AUTOSAR XML (schema 4-0-3)
standard types defined: Boolean, UInt16, UInt8
package /AUTOSAR_Platform/DataConstrs
  range DC_Boolean: raw 0..1
  range DC_UInt16: raw 0..65535
  range DC_UInt8: raw 0..255
package /PATAC/MSM/ComponentTypes
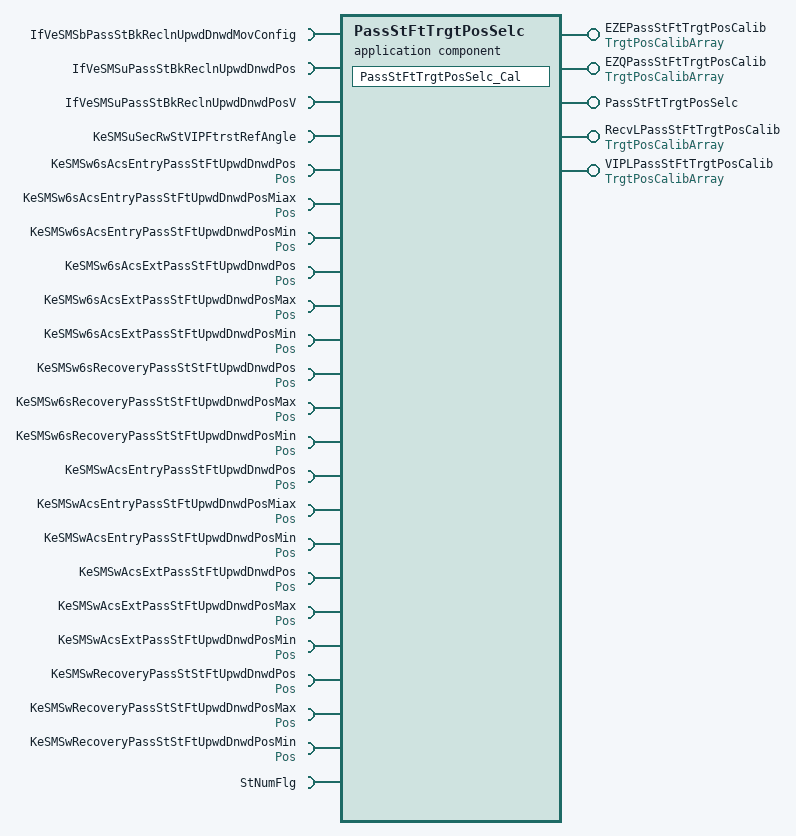
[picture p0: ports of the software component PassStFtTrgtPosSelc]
  application sw component type PassStFtTrgtPosSelc
    5 x provide port:
      EZEPassStFtTrgtPosCalib: nonqueued-sender-com-spec{data-element=TrgtPosArray, init-value=[4095, 4095, 4095]}, provided-interface=TrgtPosCalibArray
      EZQPassStFtTrgtPosCalib: nonqueued-sender-com-spec{data-element=TrgtPosArray, init-value=[4095, 4095, 4095]}, provided-interface=TrgtPosCalibArray
      PassStFtTrgtPosSelc: server-com-spec{operation=Cal, queue-length=1}, provided-interface=PassStFtTrgtPosSelc
      RecvLPassStFtTrgtPosCalib: nonqueued-sender-com-spec{data-element=TrgtPosArray, init-value=[4095, 4095, 4095]}, provided-interface=TrgtPosCalibArray
      VIPLPassStFtTrgtPosCalib: nonqueued-sender-com-spec{data-element=TrgtPosArray, init-value=[4095, 4095, 4095]}, provided-interface=TrgtPosCalibArray
    23 x require port:
      IfVeSMSbPassStBkReclnUpwdDnwdMovConfig: nonqueued-receiver-com-spec{data-element=IfVeSMSbPassStBkReclnUpwdDnwdMovConfig/Val, filter=data-filter-type=ALWAYS, init-value=0}, required-interface=IfVeSMSbPassStBkReclnUpwdDnwdMovConfig
      IfVeSMSuPassStBkReclnUpwdDnwdPos: nonqueued-receiver-com-spec{data-element=IfVeSMSuPassStBkReclnUpwdDnwdPos/Val, filter=data-filter-type=ALWAYS, init-value=0}, required-interface=IfVeSMSuPassStBkReclnUpwdDnwdPos
      IfVeSMSuPassStBkReclnUpwdDnwdPosV: nonqueued-receiver-com-spec{data-element=IfVeSMSuPassStBkReclnUpwdDnwdPosV/Val, filter=data-filter-type=ALWAYS, init-value=0}, required-interface=IfVeSMSuPassStBkReclnUpwdDnwdPosV
      KeSMSuSecRwStVIPFtrstRefAngle: parameter-require-com-spec{init-value=110, parameter=KeSMSuSecRwStVIPFtrstRefAngle/Val}, required-interface=KeSMSuSecRwStVIPFtrstRefAngle
      KeSMSw6sAcsEntryPassStFtUpwdDnwdPos: parameter-require-com-spec{init-value=0, parameter=Pos/Val}, required-interface=Pos
      KeSMSw6sAcsEntryPassStFtUpwdDnwdPosMiax: parameter-require-com-spec{init-value=0, parameter=Pos/Val}, required-interface=Pos
      KeSMSw6sAcsEntryPassStFtUpwdDnwdPosMin: parameter-require-com-spec{init-value=0, parameter=Pos/Val}, required-interface=Pos
      KeSMSw6sAcsExtPassStFtUpwdDnwdPos: parameter-require-com-spec{init-value=0, parameter=Pos/Val}, required-interface=Pos
      KeSMSw6sAcsExtPassStFtUpwdDnwdPosMax: parameter-require-com-spec{init-value=0, parameter=Pos/Val}, required-interface=Pos
      KeSMSw6sAcsExtPassStFtUpwdDnwdPosMin: parameter-require-com-spec{init-value=0, parameter=Pos/Val}, required-interface=Pos
      KeSMSw6sRecoveryPassStStFtUpwdDnwdPos: parameter-require-com-spec{init-value=0, parameter=Pos/Val}, required-interface=Pos
      KeSMSw6sRecoveryPassStStFtUpwdDnwdPosMax: parameter-require-com-spec{init-value=0, parameter=Pos/Val}, required-interface=Pos
      KeSMSw6sRecoveryPassStStFtUpwdDnwdPosMin: parameter-require-com-spec{init-value=0, parameter=Pos/Val}, required-interface=Pos
      KeSMSwAcsEntryPassStFtUpwdDnwdPos: parameter-require-com-spec{init-value=0, parameter=Pos/Val}, required-interface=Pos
      KeSMSwAcsEntryPassStFtUpwdDnwdPosMiax: parameter-require-com-spec{init-value=0, parameter=Pos/Val}, required-interface=Pos
      KeSMSwAcsEntryPassStFtUpwdDnwdPosMin: parameter-require-com-spec{init-value=0, parameter=Pos/Val}, required-interface=Pos
      KeSMSwAcsExtPassStFtUpwdDnwdPos: parameter-require-com-spec{init-value=0, parameter=Pos/Val}, required-interface=Pos
      KeSMSwAcsExtPassStFtUpwdDnwdPosMax: parameter-require-com-spec{init-value=0, parameter=Pos/Val}, required-interface=Pos
      KeSMSwAcsExtPassStFtUpwdDnwdPosMin: parameter-require-com-spec{init-value=0, parameter=Pos/Val}, required-interface=Pos
      KeSMSwRecoveryPassStStFtUpwdDnwdPos: parameter-require-com-spec{init-value=0, parameter=Pos/Val}, required-interface=Pos
      KeSMSwRecoveryPassStStFtUpwdDnwdPosMax: parameter-require-com-spec{init-value=0, parameter=Pos/Val}, required-interface=Pos
      KeSMSwRecoveryPassStStFtUpwdDnwdPosMin: parameter-require-com-spec{init-value=0, parameter=Pos/Val}, required-interface=Pos
      StNumFlg: required-interface=StNumFlg
        required-com-specs:
          data-element=Is4s, filter=data-filter-type=ALWAYS, init-value=0
          data-element=Is6s, filter=data-filter-type=ALWAYS, init-value=0
          data-element=Is6s7s, filter=data-filter-type=ALWAYS, init-value=0
          data-element=Is7s, filter=data-filter-type=ALWAYS, init-value=0
    behavior PassStFtTrgtPosSelc_InternalBehavior
      operation invoked event OIT_PassStFtTrgtPosSelc_Cal_PassStFtTrgtPosSelc_Cal: start-on-event=PassStFtTrgtPosSelc_Cal, operation=PassStFtTrgtPosSelc.Cal
      runnable PassStFtTrgtPosSelc_Cal
        data-receive-point-by-arguments:
          7 x access:
            REC_IfVeSMSbPassStBkReclnUpwdDnwdMovConfig_Val: accessed-variable=IfVeSMSbPassStBkReclnUpwdDnwdMovConfig.Val
            REC_IfVeSMSuPassStBkReclnUpwdDnwdPos_Val: accessed-variable=IfVeSMSuPassStBkReclnUpwdDnwdPos.Val
            REC_IfVeSMSuPassStBkReclnUpwdDnwdPosV_Val: accessed-variable=IfVeSMSuPassStBkReclnUpwdDnwdPosV.Val
            REC_StNumFlg_Is4s: accessed-variable=StNumFlg.Is4s
            REC_StNumFlg_Is6s: accessed-variable=StNumFlg.Is6s
            REC_StNumFlg_Is6s7s: accessed-variable=StNumFlg.Is6s7s
            REC_StNumFlg_Is7s: accessed-variable=StNumFlg.Is7s
        data-send-points:
          4 x access:
            SEND_EZEPassStFtTrgtPosCalib_TrgtPosArray: accessed-variable=EZEPassStFtTrgtPosCalib.TrgtPosArray
            SEND_EZQPassStFtTrgtPosCalib_TrgtPosArray: accessed-variable=EZQPassStFtTrgtPosCalib.TrgtPosArray
            SEND_RecvLPassStFtTrgtPosCalib_TrgtPosArray: accessed-variable=RecvLPassStFtTrgtPosCalib.TrgtPosArray
            SEND_VIPLPassStFtTrgtPosCalib_TrgtPosArray: accessed-variable=VIPLPassStFtTrgtPosCalib.TrgtPosArray
        19 x parameter access:
          PA_KeSMSuSecRwStVIPFtrstRefAngle_Val: accessed-parameter=KeSMSuSecRwStVIPFtrstRefAngle.Val
          PA_KeSMSw6sAcsEntryPassStFtUpwdDnwdPos_Val: accessed-parameter=KeSMSw6sAcsEntryPassStFtUpwdDnwdPos.Val
          PA_KeSMSw6sAcsEntryPassStFtUpwdDnwdPosMiax_Val: accessed-parameter=KeSMSw6sAcsEntryPassStFtUpwdDnwdPosMiax.Val
          PA_KeSMSw6sAcsEntryPassStFtUpwdDnwdPosMin_Val: accessed-parameter=KeSMSw6sAcsEntryPassStFtUpwdDnwdPosMin.Val
          PA_KeSMSw6sAcsExtPassStFtUpwdDnwdPos_Val: accessed-parameter=KeSMSw6sAcsExtPassStFtUpwdDnwdPos.Val
          PA_KeSMSw6sAcsExtPassStFtUpwdDnwdPosMax_Val: accessed-parameter=KeSMSw6sAcsExtPassStFtUpwdDnwdPosMax.Val
          PA_KeSMSw6sAcsExtPassStFtUpwdDnwdPosMin_Val: accessed-parameter=KeSMSw6sAcsExtPassStFtUpwdDnwdPosMin.Val
          PA_KeSMSw6sRecoveryPassStStFtUpwdDnwdPos_Val: accessed-parameter=KeSMSw6sRecoveryPassStStFtUpwdDnwdPos.Val
          PA_KeSMSw6sRecoveryPassStStFtUpwdDnwdPosMax_Val: accessed-parameter=KeSMSw6sRecoveryPassStStFtUpwdDnwdPosMax.Val
          PA_KeSMSw6sRecoveryPassStStFtUpwdDnwdPosMin_Val: accessed-parameter=KeSMSw6sRecoveryPassStStFtUpwdDnwdPosMin.Val
          PA_KeSMSwAcsEntryPassStFtUpwdDnwdPos_Val: accessed-parameter=KeSMSwAcsEntryPassStFtUpwdDnwdPos.Val
          PA_KeSMSwAcsEntryPassStFtUpwdDnwdPosMiax_Val: accessed-parameter=KeSMSwAcsEntryPassStFtUpwdDnwdPosMiax.Val
          PA_KeSMSwAcsEntryPassStFtUpwdDnwdPosMin_Val: accessed-parameter=KeSMSwAcsEntryPassStFtUpwdDnwdPosMin.Val
          PA_KeSMSwAcsExtPassStFtUpwdDnwdPos_Val: accessed-parameter=KeSMSwAcsExtPassStFtUpwdDnwdPos.Val
          PA_KeSMSwAcsExtPassStFtUpwdDnwdPosMax_Val: accessed-parameter=KeSMSwAcsExtPassStFtUpwdDnwdPosMax.Val
          PA_KeSMSwAcsExtPassStFtUpwdDnwdPosMin_Val: accessed-parameter=KeSMSwAcsExtPassStFtUpwdDnwdPosMin.Val
          PA_KeSMSwRecoveryPassStStFtUpwdDnwdPos_Val: accessed-parameter=KeSMSwRecoveryPassStStFtUpwdDnwdPos.Val
          PA_KeSMSwRecoveryPassStStFtUpwdDnwdPosMax_Val: accessed-parameter=KeSMSwRecoveryPassStStFtUpwdDnwdPosMax.Val
          PA_KeSMSwRecoveryPassStStFtUpwdDnwdPosMin_Val: accessed-parameter=KeSMSwRecoveryPassStStFtUpwdDnwdPosMin.Val
  swc implementation PassStFtTrgtPosSelc_Implementation: behavior=PassStFtTrgtPosSelc_InternalBehavior
    code-descriptors:
      code Default: artifact-descriptors=autosar-engineering-object={short-label=Default, category=SWSRC}
package /PATAC/MSM/ModeAdjust/CalPortInterface
  parameter interface Pos
    parameter data prototype Val: sw-calibration-access=READ-WRITE, type=UInt16
package /PATAC/MSM/ModeAdjust/DataType
  impl type TrgtPosCalibArray: category=ARRAY, sw-calibration-access=READ-ONLY, type-emitter=RTE  # 0:pos 1:max 2:min
    element Element: array-size=3, array-size-semantics=FIXED-SIZE, implementation-data-type=UInt16, invalid-value=0
package /PATAC/MSM/ModeAdjust/Interfaces
  sender receiver interface IfVeSMSuPassStBkReclnUpwdDnwdPosV: invalidation-policy{data-element=IfVeSMSuPassStBkReclnUpwdDnwdPosV/Val, handle-invalid=DONT-INVALIDATE}
    data Val: type=Boolean
package /PATAC/MSM/ModeAdjust/PortInterface
  client server interface PassStFtTrgtPosSelc
    operation Cal
  sender receiver interface StNumFlg
    4 x data, all with type=Boolean:
      Is4s
      Is6s
      Is6s7s
      Is7s
    invalidation-policys:
      data-element=Is7s, handle-invalid=DONT-INVALIDATE
      data-element=Is6s, handle-invalid=DONT-INVALIDATE
      data-element=Is4s, handle-invalid=DONT-INVALIDATE
      data-element=Is6s7s, handle-invalid=DONT-INVALIDATE
  sender receiver interface TrgtPosCalibArray: invalidation-policy{data-element=TrgtPosArray, handle-invalid=DONT-INVALIDATE}
    data TrgtPosArray: type=TrgtPosCalibArray  # 0:Pos 1:Max 2:Min
package /PATAC/MSM/PortInterfaces
  parameter interface KeSMSuSecRwStVIPFtrstRefAngle
    parameter data prototype Val: sw-calibration-access=READ-WRITE, type=UInt8
  sender receiver interface IfVeSMSbPassStBkReclnUpwdDnwdMovConfig: invalidation-policy{data-element=IfVeSMSbPassStBkReclnUpwdDnwdMovConfig/Val, handle-invalid=DONT-INVALIDATE}
    data Val: type=Boolean
  sender receiver interface IfVeSMSuPassStBkReclnUpwdDnwdPos: invalidation-policy{data-element=IfVeSMSuPassStBkReclnUpwdDnwdPos/Val, handle-invalid=DONT-INVALIDATE}
    data Val: type=UInt16
